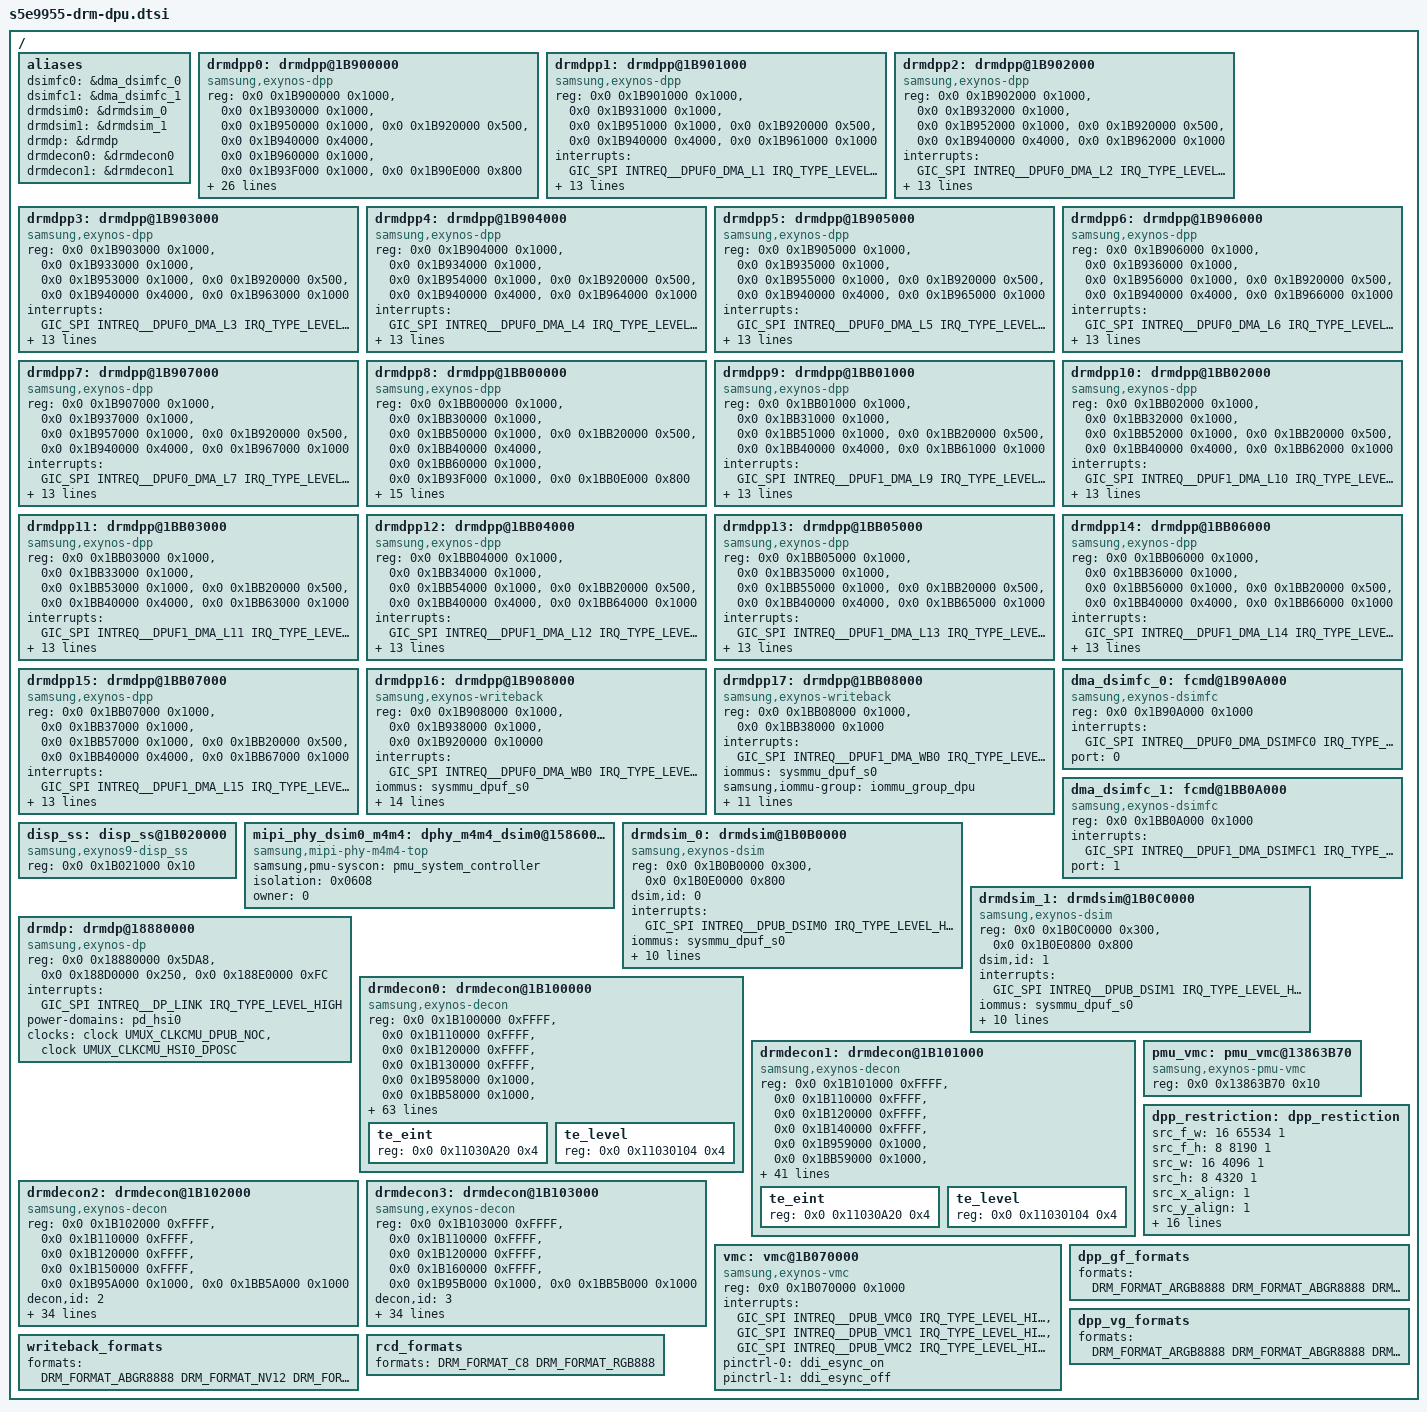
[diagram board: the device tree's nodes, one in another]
/*
 * SAMSUNG EXYNOS9945 SoC device tree source
 *
 * Copyright (c) 2021 Samsung Electronics Co., Ltd.
 *		http://www.samsung.com
 *
 * SAMSUNG EXYNOS9945 SoC device nodes are listed in this file.
 * EXYNOS based board files can include this file and provide
 * values for board specfic bindings.
 *
 * This program is free software; you can redistribute it and/or modify
 * it under the terms of the GNU General Public License version 2 as
 * published by the Free Software Foundation.
 */

#include <dt-bindings/interrupt-controller/arm-gic.h>
#include <dt-bindings/interrupt-controller/s5e9955.h>
#include <dt-bindings/clock/s5e9955.h>
#include <dt-bindings/soc/samsung/s5e9955-devfreq.h>
#include <dt-bindings/display/exynos-display.h>
#include "s5e9955-pinctrl.dtsi"
#include "s5e9955-display-timing.dtsi"
#include "s5e9955-pm-domains.dtsi"

/ {
	aliases {
		dsimfc0 = &dma_dsimfc_0;
		dsimfc1 = &dma_dsimfc_1;
		drmdsim0 = &drmdsim_0;
		drmdsim1 = &drmdsim_1;
		drmdp = &drmdp;
		drmdecon0 = &drmdecon0;
		drmdecon1 = &drmdecon1;
	};

	drmdpp0: drmdpp@1B900000 {	/* L0 */
		compatible = "samsung,exynos-dpp";
		reg = <0x0 0x1B900000 0x1000>,	/* DPU_DMA */
		      <0x0 0x1B930000 0x1000>,	/* DPP */
		      <0x0 0x1B950000 0x1000>,	/* SRAMCON */
		      <0x0 0x1B920000 0x500>,	/* vOTF_DPUF0 */
		      <0x0 0x1B940000 0x4000>,  /* SCL_COEF */
		      <0x0 0x1B960000 0x1000>,  /* HDR_COMM */
		      <0x0 0x1B93F000 0x1000>,  /* DPP_DEBUG */
		      <0x0 0x1B90E000 0x800>;   /* SFR_DMA */
		reg-names = "dma", "dpp", "sramc", "votf",
			    "scl_coef", "hdr_comm", "dpp_debug", "sfr_dma";

		/* DPU_DMA IRQ, DPP IRQ, SFR_DMA IRQ */
		interrupts = <GIC_SPI INTREQ__DPUF0_DMA_L0 IRQ_TYPE_LEVEL_HIGH>;
		interrupt-names = "dma";

		iommus = <&sysmmu_dpuf_s0>;
		samsung,iommu-group = <&iommu_group_dpu>;
		/* vOTF_MSCL(for vOTF sysmmu) */
		samsung,iommu-identity-map = <0x0 0x1D890000 0x10000>;

		attr = <(DPP_ATTR_SAJC | DPP_ATTR_FLIP | DPP_ATTR_IDMA |
			DPP_ATTR_DPP | DPP_ATTR_SRAMC | DPP_ATTR_HDR_COMM)>;
		port = <0>; /* AXI port number */

		/* 1: scale X, 2: 1/2x scale down, 4: 1/4x scale down */
		scale_down = <1>;
		/* 1: scale X, 2: 2x scale up, 4: 4x scale up */
		scale_up = <1>;

		dpp,id = <0>;
		dpuf,id = <0>;
		dpp,formats = <&dpp_gf_formats>;
		dpp,restriction = <&dpp_restriction>;
		dpp,comp-transform-support = <(COMP_RGB_FLIP_ALL)>;

		//dpp,rsc_check;
		rsc_sajc = <1>;
		rsc_sbwc = <2>;
		rsc_rot = <1>;
		rsc_scl = <2>;
		rsc_itp_csc = <4>;
		rsc_sramc = <2>;
		rsc_sram_w = <1024>;
		rsc_sram = <42>;

		dpp,enable-dma-write-mode;
	};

	drmdpp1: drmdpp@1B901000 {	/* L1 */
		compatible = "samsung,exynos-dpp";
		reg = <0x0 0x1B901000 0x1000>,
		      <0x0 0x1B931000 0x1000>,
		      <0x0 0x1B951000 0x1000>,
		      <0x0 0x1B920000 0x500>,
		      <0x0 0x1B940000 0x4000>,
		      <0x0 0x1B961000 0x1000>;
		reg-names = "dma", "dpp", "sramc", "votf", "scl_coef", "hdr_comm";

		interrupts = <GIC_SPI INTREQ__DPUF0_DMA_L1 IRQ_TYPE_LEVEL_HIGH>;
		interrupt-names = "dma";

		iommus = <&sysmmu_dpuf_s0>;
		samsung,iommu-group = <&iommu_group_dpu>;

		attr = <(DPP_ATTR_SAJC | DPP_ATTR_FLIP | DPP_ATTR_ROT |
			DPP_ATTR_CSC | DPP_ATTR_SCALE |	DPP_ATTR_SBWC |
			DPP_ATTR_IDMA |	DPP_ATTR_DPP | DPP_ATTR_SRAMC |
			DPP_ATTR_HDR_COMM)>;
		port = <0>;
		scale_down = <4>;
		scale_up = <8>;

		dpp,id = <1>;
		dpuf,id = <0>;
		dpp,formats = <&dpp_vg_formats>;
		dpp,restriction = <&dpp_restriction>;
		dpp,comp-transform-support = <(COMP_YUV420_ALL | COMP_RGB_FLIP_ALL)>;
	};

	drmdpp2: drmdpp@1B902000 {	/* L2 */
		compatible = "samsung,exynos-dpp";
		reg = <0x0 0x1B902000 0x1000>,
		      <0x0 0x1B932000 0x1000>,
		      <0x0 0x1B952000 0x1000>,
		      <0x0 0x1B920000 0x500>,
		      <0x0 0x1B940000 0x4000>,
		      <0x0 0x1B962000 0x1000>;
		reg-names = "dma", "dpp", "sramc", "votf", "scl_coef", "hdr_comm";

		interrupts = <GIC_SPI INTREQ__DPUF0_DMA_L2 IRQ_TYPE_LEVEL_HIGH>;
		interrupt-names = "dma";

		iommus = <&sysmmu_dpuf_s0>;
		samsung,iommu-group = <&iommu_group_dpu>;

		attr = <(DPP_ATTR_SAJC | DPP_ATTR_FLIP | DPP_ATTR_IDMA |
			DPP_ATTR_DPP | DPP_ATTR_SRAMC | DPP_ATTR_HDR_COMM)>;
		port = <0>;
		scale_down = <1>;
		scale_up = <1>;

		dpp,id = <2>;
		dpuf,id = <0>;
		dpp,formats = <&dpp_gf_formats>;
		dpp,restriction = <&dpp_restriction>;
		dpp,comp-transform-support = <(COMP_RGB_FLIP_ALL)>;
	};

	drmdpp3: drmdpp@1B903000 {	/* L3 */
		compatible = "samsung,exynos-dpp";
		reg = <0x0 0x1B903000 0x1000>,
		      <0x0 0x1B933000 0x1000>,
		      <0x0 0x1B953000 0x1000>,
		      <0x0 0x1B920000 0x500>,
		      <0x0 0x1B940000 0x4000>,
		      <0x0 0x1B963000 0x1000>;
		reg-names = "dma", "dpp", "sramc", "votf", "scl_coef", "hdr_comm";

		interrupts = <GIC_SPI INTREQ__DPUF0_DMA_L3 IRQ_TYPE_LEVEL_HIGH>;
		interrupt-names = "dma";

		iommus = <&sysmmu_dpuf_s0>;
		samsung,iommu-group = <&iommu_group_dpu>;

		attr = <(DPP_ATTR_SAJC | DPP_ATTR_FLIP | DPP_ATTR_ROT |
			DPP_ATTR_CSC | DPP_ATTR_SCALE |	DPP_ATTR_SBWC |
			DPP_ATTR_IDMA |	DPP_ATTR_DPP | DPP_ATTR_SRAMC |
			DPP_ATTR_HDR_COMM)>;
		port = <0>;
		scale_down = <4>;
		scale_up = <8>;

		dpp,id = <3>;
		dpuf,id = <0>;
		dpp,formats = <&dpp_vg_formats>;
		dpp,restriction = <&dpp_restriction>;
		dpp,comp-transform-support = <(COMP_YUV420_ALL | COMP_RGB_FLIP_ALL)>;
	};

	drmdpp4: drmdpp@1B904000 {	/* L4 */
		compatible = "samsung,exynos-dpp";
		reg = <0x0 0x1B904000 0x1000>,
		      <0x0 0x1B934000 0x1000>,
		      <0x0 0x1B954000 0x1000>,
		      <0x0 0x1B920000 0x500>,
		      <0x0 0x1B940000 0x4000>,
		      <0x0 0x1B964000 0x1000>;
		reg-names = "dma", "dpp", "sramc", "votf", "scl_coef", "hdr_comm";

		interrupts = <GIC_SPI INTREQ__DPUF0_DMA_L4 IRQ_TYPE_LEVEL_HIGH>;
		interrupt-names = "dma";

		iommus = <&sysmmu_dpuf_s0>;
		samsung,iommu-group = <&iommu_group_dpu>;

		attr = <(DPP_ATTR_SAJC | DPP_ATTR_FLIP | DPP_ATTR_IDMA |
			DPP_ATTR_DPP | DPP_ATTR_SRAMC | DPP_ATTR_HDR_COMM)>;
		port = <1>;
		scale_down = <1>;
		scale_up = <1>;

		dpp,id = <4>;
		dpuf,id = <0>;
		dpp,formats = <&dpp_gf_formats>;
		dpp,restriction = <&dpp_restriction>;
		dpp,comp-transform-support = <(COMP_RGB_FLIP_ALL)>;
	};

	drmdpp5: drmdpp@1B905000 {	/* L5 */
		compatible = "samsung,exynos-dpp";
		reg = <0x0 0x1B905000 0x1000>,
		      <0x0 0x1B935000 0x1000>,
		      <0x0 0x1B955000 0x1000>,
		      <0x0 0x1B920000 0x500>,
		      <0x0 0x1B940000 0x4000>,
		      <0x0 0x1B965000 0x1000>;
		reg-names = "dma", "dpp", "sramc", "votf", "scl_coef", "hdr_comm";

		interrupts = <GIC_SPI INTREQ__DPUF0_DMA_L5 IRQ_TYPE_LEVEL_HIGH>;
		interrupt-names = "dma";

		iommus = <&sysmmu_dpuf_s0>;
		samsung,iommu-group = <&iommu_group_dpu>;

		attr = <(DPP_ATTR_SAJC | DPP_ATTR_FLIP | DPP_ATTR_ROT |
			DPP_ATTR_CSC | DPP_ATTR_SCALE |	DPP_ATTR_SBWC |
			DPP_ATTR_IDMA |	DPP_ATTR_DPP | DPP_ATTR_SRAMC |
			DPP_ATTR_HDR_COMM)>;
		port = <1>;
		scale_down = <4>;
		scale_up = <8>;

		dpp,id = <5>;
		dpuf,id = <0>;
		dpp,formats = <&dpp_vg_formats>;
		dpp,restriction = <&dpp_restriction>;
		dpp,comp-transform-support = <(COMP_YUV420_ALL | COMP_RGB_FLIP_ALL)>;
	};

	drmdpp6: drmdpp@1B906000 {	/* L6 */
		compatible = "samsung,exynos-dpp";
		reg = <0x0 0x1B906000 0x1000>,
		      <0x0 0x1B936000 0x1000>,
		      <0x0 0x1B956000 0x1000>,
		      <0x0 0x1B920000 0x500>,
		      <0x0 0x1B940000 0x4000>,
		      <0x0 0x1B966000 0x1000>;
		reg-names = "dma", "dpp", "sramc", "votf", "scl_coef", "hdr_comm";

		interrupts = <GIC_SPI INTREQ__DPUF0_DMA_L6 IRQ_TYPE_LEVEL_HIGH>;
		interrupt-names = "dma";

		iommus = <&sysmmu_dpuf_s0>;
		samsung,iommu-group = <&iommu_group_dpu>;

		attr = <(DPP_ATTR_SAJC | DPP_ATTR_FLIP | DPP_ATTR_IDMA |
			DPP_ATTR_DPP | DPP_ATTR_SRAMC | DPP_ATTR_HDR_COMM)>;
		port = <1>;
		scale_down = <1>;
		scale_up = <1>;

		dpp,id = <6>;
		dpuf,id = <0>;
		dpp,formats = <&dpp_gf_formats>;
		dpp,restriction = <&dpp_restriction>;
		dpp,comp-transform-support = <(COMP_RGB_FLIP_ALL)>;
	};

	drmdpp7: drmdpp@1B907000 {	/* L7 */
		compatible = "samsung,exynos-dpp";
		reg = <0x0 0x1B907000 0x1000>,
		      <0x0 0x1B937000 0x1000>,
		      <0x0 0x1B957000 0x1000>,
		      <0x0 0x1B920000 0x500>,
		      <0x0 0x1B940000 0x4000>,
		      <0x0 0x1B967000 0x1000>;
		reg-names = "dma", "dpp", "sramc", "votf", "scl_coef", "hdr_comm";

		interrupts = <GIC_SPI INTREQ__DPUF0_DMA_L7 IRQ_TYPE_LEVEL_HIGH>;
		interrupt-names = "dma";

		iommus = <&sysmmu_dpuf_s0>;
		samsung,iommu-group = <&iommu_group_dpu>;

		attr = <(DPP_ATTR_SAJC | DPP_ATTR_FLIP | DPP_ATTR_ROT |
			DPP_ATTR_CSC | DPP_ATTR_SCALE |	DPP_ATTR_SBWC |
			DPP_ATTR_IDMA |	DPP_ATTR_DPP | DPP_ATTR_SRAMC |
			DPP_ATTR_HDR_COMM)>;
		port = <1>;
		scale_down = <4>;
		scale_up = <8>;

		dpp,id = <7>;
		dpuf,id = <0>;
		dpp,formats = <&dpp_vg_formats>;
		dpp,restriction = <&dpp_restriction>;
		dpp,comp-transform-support = <(COMP_YUV420_ALL | COMP_RGB_FLIP_ALL)>;
	};

	drmdpp8: drmdpp@1BB00000 {	/* L8 */
		compatible = "samsung,exynos-dpp";
		reg = <0x0 0x1BB00000 0x1000>,
		      <0x0 0x1BB30000 0x1000>,
		      <0x0 0x1BB50000 0x1000>,
		      <0x0 0x1BB20000 0x500>,
		      <0x0 0x1BB40000 0x4000>,
		      <0x0 0x1BB60000 0x1000>,
		      <0x0 0x1B93F000 0x1000>,
		      <0x0 0x1BB0E000 0x800>;
		reg-names = "dma", "dpp", "sramc", "votf", "scl_coef",
			"hdr_comm", "dpp_debug", "sfr_dma";

		interrupts = <GIC_SPI INTREQ__DPUF1_DMA_L8 IRQ_TYPE_LEVEL_HIGH>;
		interrupt-names = "dma";

		iommus = <&sysmmu_dpuf_s0>;
		samsung,iommu-group = <&iommu_group_dpu>;

		attr = <(DPP_ATTR_SAJC | DPP_ATTR_FLIP | DPP_ATTR_IDMA |
			DPP_ATTR_DPP | DPP_ATTR_SRAMC | DPP_ATTR_HDR_COMM)>;
		port = <1>;
		scale_down = <1>;
		scale_up = <1>;

		dpp,id = <8>;
		dpuf,id = <1>;
		dpp,formats = <&dpp_gf_formats>;
		dpp,restriction = <&dpp_restriction>;
		dpp,comp-transform-support = <(COMP_RGB_FLIP_ALL)>;
	};

	drmdpp9: drmdpp@1BB01000 {	/* L9 */
		compatible = "samsung,exynos-dpp";
		reg = <0x0 0x1BB01000 0x1000>,
		      <0x0 0x1BB31000 0x1000>,
		      <0x0 0x1BB51000 0x1000>,
		      <0x0 0x1BB20000 0x500>,
		      <0x0 0x1BB40000 0x4000>,
		      <0x0 0x1BB61000 0x1000>;
		reg-names = "dma", "dpp", "sramc", "votf", "scl_coef", "hdr_comm";

		interrupts = <GIC_SPI INTREQ__DPUF1_DMA_L9 IRQ_TYPE_LEVEL_HIGH>;
		interrupt-names = "dma";

		iommus = <&sysmmu_dpuf_s0>;
		samsung,iommu-group = <&iommu_group_dpu>;

		attr = <(DPP_ATTR_SAJC | DPP_ATTR_FLIP | DPP_ATTR_ROT |
			DPP_ATTR_CSC | DPP_ATTR_SCALE |	DPP_ATTR_SBWC |
			DPP_ATTR_IDMA |	DPP_ATTR_DPP | DPP_ATTR_SRAMC |
			DPP_ATTR_HDR_COMM)>;
		port = <1>;
		scale_down = <4>;
		scale_up = <8>;

		dpp,id = <9>;
		dpuf,id = <1>;
		dpp,formats = <&dpp_vg_formats>;
		dpp,restriction = <&dpp_restriction>;
		dpp,comp-transform-support = <(COMP_YUV420_ALL | COMP_RGB_FLIP_ALL)>;
	};

	drmdpp10: drmdpp@1BB02000 {	/* L10 */
		compatible = "samsung,exynos-dpp";
		reg = <0x0 0x1BB02000 0x1000>,
		      <0x0 0x1BB32000 0x1000>,
		      <0x0 0x1BB52000 0x1000>,
		      <0x0 0x1BB20000 0x500>,
		      <0x0 0x1BB40000 0x4000>,
		      <0x0 0x1BB62000 0x1000>;
		reg-names = "dma", "dpp", "sramc", "votf", "scl_coef", "hdr_comm";

		interrupts = <GIC_SPI INTREQ__DPUF1_DMA_L10 IRQ_TYPE_LEVEL_HIGH>;
		interrupt-names = "dma";

		iommus = <&sysmmu_dpuf_s0>;
		samsung,iommu-group = <&iommu_group_dpu>;

		attr = <(DPP_ATTR_SAJC | DPP_ATTR_FLIP | DPP_ATTR_IDMA |
			DPP_ATTR_DPP | DPP_ATTR_SRAMC | DPP_ATTR_HDR_COMM)>;
		port = <1>;
		scale_down = <1>;
		scale_up = <1>;

		dpp,id = <10>;
		dpuf,id = <1>;
		dpp,formats = <&dpp_gf_formats>;
		dpp,restriction = <&dpp_restriction>;
		dpp,comp-transform-support = <(COMP_RGB_FLIP_ALL)>;
	};

	drmdpp11: drmdpp@1BB03000 {	/* L11 */
		compatible = "samsung,exynos-dpp";
		reg = <0x0 0x1BB03000 0x1000>,
		      <0x0 0x1BB33000 0x1000>,
		      <0x0 0x1BB53000 0x1000>,
		      <0x0 0x1BB20000 0x500>,
		      <0x0 0x1BB40000 0x4000>,
		      <0x0 0x1BB63000 0x1000>;
		reg-names = "dma", "dpp", "sramc", "votf", "scl_coef", "hdr_comm";

		interrupts = <GIC_SPI INTREQ__DPUF1_DMA_L11 IRQ_TYPE_LEVEL_HIGH>;
		interrupt-names = "dma";

		iommus = <&sysmmu_dpuf_s0>;
		samsung,iommu-group = <&iommu_group_dpu>;

		attr = <(DPP_ATTR_SAJC | DPP_ATTR_FLIP | DPP_ATTR_ROT |
			DPP_ATTR_CSC | DPP_ATTR_SCALE |	DPP_ATTR_SBWC |
			DPP_ATTR_IDMA |	DPP_ATTR_DPP | DPP_ATTR_SRAMC |
			DPP_ATTR_HDR_COMM)>;
		port = <1>;
		scale_down = <4>;
		scale_up = <8>;

		dpp,id = <11>;
		dpuf,id = <1>;
		dpp,formats = <&dpp_vg_formats>;
		dpp,restriction = <&dpp_restriction>;
		dpp,comp-transform-support = <(COMP_YUV420_ALL | COMP_RGB_FLIP_ALL)>;
	};

	drmdpp12: drmdpp@1BB04000 {	/* L12 */
		compatible = "samsung,exynos-dpp";
		reg = <0x0 0x1BB04000 0x1000>,
		      <0x0 0x1BB34000 0x1000>,
		      <0x0 0x1BB54000 0x1000>,
		      <0x0 0x1BB20000 0x500>,
		      <0x0 0x1BB40000 0x4000>,
		      <0x0 0x1BB64000 0x1000>;
		reg-names = "dma", "dpp", "sramc", "votf", "scl_coef", "hdr_comm";

		interrupts = <GIC_SPI INTREQ__DPUF1_DMA_L12 IRQ_TYPE_LEVEL_HIGH>;
		interrupt-names = "dma";

		iommus = <&sysmmu_dpuf_s0>;
		samsung,iommu-group = <&iommu_group_dpu>;

		attr = <(DPP_ATTR_SAJC | DPP_ATTR_FLIP | DPP_ATTR_IDMA |
			DPP_ATTR_DPP | DPP_ATTR_SRAMC | DPP_ATTR_HDR_COMM)>;
		port = <0>;
		scale_down = <1>;
		scale_up = <1>;

		dpp,id = <12>;
		dpuf,id = <1>;
		dpp,formats = <&dpp_gf_formats>;
		dpp,restriction = <&dpp_restriction>;
		dpp,comp-transform-support = <(COMP_RGB_FLIP_ALL)>;
	};

	drmdpp13: drmdpp@1BB05000 {	/* L13 */
		compatible = "samsung,exynos-dpp";
		reg = <0x0 0x1BB05000 0x1000>,
		      <0x0 0x1BB35000 0x1000>,
		      <0x0 0x1BB55000 0x1000>,
		      <0x0 0x1BB20000 0x500>,
		      <0x0 0x1BB40000 0x4000>,
		      <0x0 0x1BB65000 0x1000>;
		reg-names = "dma", "dpp", "sramc", "votf", "scl_coef", "hdr_comm";

		interrupts = <GIC_SPI INTREQ__DPUF1_DMA_L13 IRQ_TYPE_LEVEL_HIGH>;
		interrupt-names = "dma";

		iommus = <&sysmmu_dpuf_s0>;
		samsung,iommu-group = <&iommu_group_dpu>;

		attr = <(DPP_ATTR_SAJC | DPP_ATTR_FLIP | DPP_ATTR_ROT |
			DPP_ATTR_CSC | DPP_ATTR_SCALE |	DPP_ATTR_SBWC |
			DPP_ATTR_IDMA |	DPP_ATTR_DPP | DPP_ATTR_SRAMC |
			DPP_ATTR_HDR_COMM)>;
		port = <0>;
		scale_down = <4>;
		scale_up = <8>;

		dpp,id = <13>;
		dpuf,id = <1>;
		dpp,formats = <&dpp_vg_formats>;
		dpp,restriction = <&dpp_restriction>;
		dpp,comp-transform-support = <(COMP_YUV420_ALL | COMP_RGB_FLIP_ALL)>;
	};

	drmdpp14: drmdpp@1BB06000 {	/* L14 */
		compatible = "samsung,exynos-dpp";
		reg = <0x0 0x1BB06000 0x1000>,
		      <0x0 0x1BB36000 0x1000>,
		      <0x0 0x1BB56000 0x1000>,
		      <0x0 0x1BB20000 0x500>,
		      <0x0 0x1BB40000 0x4000>,
		      <0x0 0x1BB66000 0x1000>;
		reg-names = "dma", "dpp", "sramc", "votf", "scl_coef", "hdr_comm";

		interrupts = <GIC_SPI INTREQ__DPUF1_DMA_L14 IRQ_TYPE_LEVEL_HIGH>;
		interrupt-names = "dma";

		iommus = <&sysmmu_dpuf_s0>;
		samsung,iommu-group = <&iommu_group_dpu>;

		attr = <(DPP_ATTR_SAJC | DPP_ATTR_FLIP | DPP_ATTR_IDMA |
			DPP_ATTR_DPP | DPP_ATTR_SRAMC | DPP_ATTR_HDR_COMM)>;
		port = <0>;
		scale_down = <1>;
		scale_up = <1>;

		dpp,id = <14>;
		dpuf,id = <1>;
		dpp,formats = <&dpp_gf_formats>;
		dpp,restriction = <&dpp_restriction>;
		dpp,comp-transform-support = <(COMP_RGB_FLIP_ALL)>;
	};

	drmdpp15: drmdpp@1BB07000 {	/* L15 */
		compatible = "samsung,exynos-dpp";
		reg = <0x0 0x1BB07000 0x1000>,
		      <0x0 0x1BB37000 0x1000>,
		      <0x0 0x1BB57000 0x1000>,
		      <0x0 0x1BB20000 0x500>,
		      <0x0 0x1BB40000 0x4000>,
		      <0x0 0x1BB67000 0x1000>;
		reg-names = "dma", "dpp", "sramc", "votf", "scl_coef", "hdr_comm";

		interrupts = <GIC_SPI INTREQ__DPUF1_DMA_L15 IRQ_TYPE_LEVEL_HIGH>;
		interrupt-names = "dma";

		iommus = <&sysmmu_dpuf_s0>;
		samsung,iommu-group = <&iommu_group_dpu>;

		attr = <(DPP_ATTR_SAJC | DPP_ATTR_FLIP | DPP_ATTR_ROT |
			DPP_ATTR_CSC | DPP_ATTR_SCALE |	DPP_ATTR_SBWC |
			DPP_ATTR_IDMA |	DPP_ATTR_DPP | DPP_ATTR_SRAMC |
			DPP_ATTR_HDR_COMM)>;
		port = <0>;
		scale_down = <4>;
		scale_up = <8>;

		dpp,id = <15>;
		dpuf,id = <1>;
		dpp,formats = <&dpp_vg_formats>;
		dpp,restriction = <&dpp_restriction>;
		dpp,comp-transform-support = <(COMP_YUV420_ALL | COMP_RGB_FLIP_ALL)>;
	};

	drmdpp16: drmdpp@1B908000 {
		compatible = "samsung,exynos-writeback";
		reg = <0x0 0x1B908000 0x1000>,
			  <0x0 0x1B938000 0x1000>,
			  <0x0 0x1B920000 0x10000>;
		reg-names = "dma", "dpp", "votf";

		interrupts = <GIC_SPI INTREQ__DPUF0_DMA_WB0 IRQ_TYPE_LEVEL_HIGH>;
		interrupt-names = "dma";

		iommus = <&sysmmu_dpuf_s0>;
		samsung,iommu-group = <&iommu_group_dpu>;
		/* vOTF_MFC(for vOTF sysmmu) */
		samsung,iommu-identity-map = <0x0 0x1E070000 0x10000>;

		attr = <(DPP_ATTR_CSC | DPP_ATTR_ODMA | DPP_ATTR_DPP)>;
		port = <1>;
		scale_down = <1>;
		scale_up = <1>;

		votf_o,enabled;
		votf_o,mfc_base = <0x1E070000>;

		dpp,id = <16>;
		dpuf,id = <0>;
		dpp,formats = <&writeback_formats>;
		dpp,restriction = <&dpp_restriction>;
	};

	drmdpp17: drmdpp@1BB08000 {
		compatible = "samsung,exynos-writeback";
		reg = <0x0 0x1BB08000 0x1000>,
			  <0x0 0x1BB38000 0x1000>;
		reg-names = "dma", "dpp";

		interrupts = <GIC_SPI INTREQ__DPUF1_DMA_WB0 IRQ_TYPE_LEVEL_HIGH>;
		interrupt-names = "dma";

		iommus = <&sysmmu_dpuf_s0>;
		samsung,iommu-group = <&iommu_group_dpu>;

		attr = <(DPP_ATTR_CSC | DPP_ATTR_ODMA | DPP_ATTR_DPP)>;
		port = <0>;
		scale_down = <1>;
		scale_up = <1>;

		votf_o,enabled;
		votf_o,mfc_base = <0x1E070000>;

		dpp,id = <17>;
		dpuf,id = <1>;
		dpp,formats = <&writeback_formats>;
		dpp,restriction = <&dpp_restriction>;
	};

	dma_dsimfc_0: fcmd@1B90A000 {	/* DPUF0_DSIMFC_L0 */
		compatible = "samsung,exynos-dsimfc";
		/* DPU_DMA */
		reg = <0x0 0x1B90A000 0x1000>;
		/* DPU_DMA IRQ */
		interrupts = <GIC_SPI INTREQ__DPUF0_DMA_DSIMFC0 IRQ_TYPE_LEVEL_HIGH>;
		interrupt-names = "dsimfc";
		port = <0>; /* AXI port number */
	};

	dma_dsimfc_1: fcmd@1BB0A000 {	/* DPUF1_DSIMFC_L1 */
		compatible = "samsung,exynos-dsimfc";
		/* DPU_DMA */
		reg = <0x0 0x1BB0A000 0x1000>;
		/* DPU_DMA IRQ */
		interrupts = <GIC_SPI INTREQ__DPUF1_DMA_DSIMFC1 IRQ_TYPE_LEVEL_HIGH>;
		interrupt-names = "dsimfc";
		port = <1>; /* AXI port number */
	};

	disp_ss: disp_ss@1B020000 {
		compatible = "samsung,exynos9-disp_ss";
		reg = <0x0 0x1B021000 0x10>;
		reg-names = "sys";
	};

	mipi_phy_dsim0_m4m4: dphy_m4m4_dsim0@15860000 {
		compatible = "samsung,mipi-phy-m4m4-top";
		samsung,pmu-syscon = <&pmu_system_controller>;
		isolation = <0x0608>;	/* offset is same as 9945 */
		owner = <0>; /* 0: DSI_0 1: DSI_1 */
		#phy-cells = <1>;
	};

	drmdsim_0: drmdsim@1B0B0000 {
		compatible = "samsung,exynos-dsim";
		reg = <0x0 0x1B0B0000 0x300>,	/* DSIM0 */
		      <0x0 0x1B0E0000 0x800>;	/* DCPHY-M0 */
		reg-names = "dsi", "dphy";

		dsim,id = <0>;

		interrupts = <GIC_SPI INTREQ__DPUB_DSIM0 IRQ_TYPE_LEVEL_HIGH>;
		interrupt-names = "dsim";

		iommus = <&sysmmu_dpuf_s0>;
		samsung,iommu-group = <&iommu_group_dpu>;

		phys = <&mipi_phy_dsim0_m4m4 0>;
		phy-names = "dsim_dphy";

		dsim_mode = <&dsim_modes>;

		clock-names = "oscclk_dsim";
		clocks = <&clock DOUT_DIV_CLK_DPUB_OSCCLK_DSIM>;

		dsi-burst-cmd = <1>;

		frequency-hopping;
		//wide-frequency-hopping;
		ulps-exit-fh-skip;

		pll-sleep = <DPHY_SLEEP_CTRL_LINK>;

		g_cmd_sram = <1024>;		/* sram for general command (unit : byte) */
		s_cmd_sram = <1024>;		/* sram for sync command (unit : byte)) */

		#address-cells = <1>;
		#size-cells = <0>;
	};

	drmdsim_1: drmdsim@1B0C0000 {
		compatible = "samsung,exynos-dsim";
		reg = <0x0 0x1B0C0000 0x300>,	/* DSIM1 */
		      <0x0 0x1B0E0800 0x800>;	/* DCPHY-M1 */
		reg-names = "dsi", "dphy";

		dsim,id = <1>;

		interrupts = <GIC_SPI INTREQ__DPUB_DSIM1 IRQ_TYPE_LEVEL_HIGH>;
		interrupt-names = "dsim";

		iommus = <&sysmmu_dpuf_s0>;
		samsung,iommu-group = <&iommu_group_dpu>;

		phys = <&mipi_phy_dsim0_m4m4 0>;
		phy-names = "dsim_dphy";

		dsim_mode = <&dsim_modes>;

		clock-names = "oscclk_dsim";
		clocks = <&clock DOUT_DIV_CLK_DPUB_OSCCLK_DSIM>;

		dsi-burst-cmd = <1>;

		frequency-hopping;
		//wide-frequency-hopping;
		ulps-exit-fh-skip;

		pll-sleep = <DPHY_SLEEP_CTRL_LINK>;

		g_cmd_sram = <1024>;		/* sram for general command (unit : byte) */
		s_cmd_sram = <1024>;		/* sram for sync command (unit : byte)) */

		#address-cells = <1>;
		#size-cells = <0>;
	};

	drmdp: drmdp@18880000 {
		compatible = "samsung,exynos-dp";
		/* IP resources(address, irq, sysmmu, power, secure, clock) */
		reg = <0x0 0x18880000 0x5DA8>,
			<0x0 0x188D0000 0x250>,
			<0x0 0x188E0000 0xFC>;
		reg-names = "dp_link", "usbdpphy_ctrl", "usbdpphy_tca_ctrl";

		interrupts = <GIC_SPI INTREQ__DP_LINK IRQ_TYPE_LEVEL_HIGH>;
		interrupt-names = "dp";

		power-domains = <&pd_hsi0>;
		/* clock */
		clock-names = "aclk", "dposc_clk";
		clocks = <&clock UMUX_CLKCMU_DPUB_NOC>, <&clock UMUX_CLKCMU_HSI0_DPOSC>;
	};

	drmdecon0: drmdecon@1B100000 {
		compatible = "samsung,exynos-decon";
		reg = <0x0 0x1B100000 0xFFFF>,	/* DECON0_MAIN */
		      <0x0 0x1B110000 0xFFFF>,	/* DECON_WIN */
		      <0x0 0x1B120000 0xFFFF>,	/* DECON_SUB */
		      <0x0 0x1B130000 0xFFFF>,	/* DECON0_WINCON */
		      <0x0 0x1B958000 0x1000>,	/* SRAMC0_D0 - DPUF0 */
		      <0x0 0x1BB58000 0x1000>,	/* SRAMC1_D0 - DPUF1 */
		      <0x0 0x1B90E000 0x1000>,  /* DQE EDMA*/
		      <0x0 0x1B170000 0xFFFF>;	/* DQE */
		reg-names = "main", "win", "sub", "wincon", "sramc_d",
			    "sramc1_d", "edma", "dqe";

		decon,id = <0>;

		interrupts = <GIC_SPI INTREQ__DPUB_DECON0_FRAME_START
				IRQ_TYPE_LEVEL_HIGH>,
			     <GIC_SPI INTREQ__DPUB_DECON0_FRAME_DONE
				IRQ_TYPE_LEVEL_HIGH>,
			     <GIC_SPI INTREQ__DPUB_DECON0_EXTRA
				IRQ_TYPE_LEVEL_HIGH>,
			     <GIC_SPI INTREQ__DPUF0_DMA_CGCTRL0
				IRQ_TYPE_LEVEL_HIGH>,
				 <GIC_SPI INTREQ__DPUF0_SRAMCON_D0
				IRQ_TYPE_LEVEL_HIGH>,
				 <GIC_SPI INTREQ__DPUF1_SRAMCON_D0
				IRQ_TYPE_LEVEL_HIGH>;
		interrupt-names = "frame_start", "frame_done", "extra",
				  "edma", "sramc_d", "sramc1_d";

		dpuf,pd-names = "pd_dpuf0", "pd_dpuf1";
		iommus = <&sysmmu_dpuf_s0>;
		samsung,iommu-group = <&iommu_group_dpu>;

		/* devfreq index */
		samsung,devfreq-idx = <DEVFREQ_MIF DEVFREQ_INT DEVFREQ_DISP>;

		/* clock */
		//clock-names = "aclk";
		//clocks = <&clock UMUX_CLKCMU_DPUB_NOC>;

		/* pinctrl */
		pinctrl-names = "hw_te_on", "hw_te_off";
		pinctrl-0 = <&decon_0_te_on>;
		pinctrl-1 = <&decon_0_te_off>;

		max_win = <16>;
		trig_mode = <0>;   /* 0: hw trigger, 1: sw trigger */
		out_type = <0x1>; /* BIT0:DSI0, BIT1:DSI1, BIT4:DP0, BIT5:DP1 */
		support-seamless-opmode-switch;

		/* 0: from DDI0, 1: from DDI1, 2: from DDI2 3: not receive TE */
		te_from = <0>;

		/* command mode svsync time (usec) */
		svsync_time_us = <1000>;
		svsync_on_fps = <120>;

		/* BTS */
		ppc = <2>;			/* pixel per clock */
		ppc_rotator = <8>;		/* rotator ppc */
		ppc_scaler = <4>;		/* scaler ppc */
		ppc_scaler_comp = <320>;	/* compressed + scaler, multipled by 100 */
		delay_comp = <4>;		/* line delay for sajc or sbwc : DMA */
		delay_scaler = <3>;		/* line delay for scaler : DPP */
		inner_width = <32>;		/* internal processing width */
		inner_util = <70>;		/* internal processing utill */
		vote-overlap-bw;

		/* bus info */
		bus_width = <32>;		/* 32-Byte : 256-bit bus */
		rot_util = <60>;		/* MIF_UTIL(65%) - 5%: UTIL gets worse at rotation */

		/* dpu dvfs */
		dfs_lv = <800000 663000 533000 468000 400000 332000 267000 200000 89000>;

		/* Urgent */
		rd_en = <1>; /* defaultly disable */
		rd_hi_thres = <0x7FF>;
		rd_lo_thres = <0x600>;
		rd_wait_cycle = <0x10>;
		wr_en = <0>; /* defaultly disable */
		wr_hi_thres = <0x0>;
		wr_lo_thres = <0x0>;

		/* DTA */
		dta_en = <0>; /* defaultly disable */
		dta_hi_thres = <0x7FC>;	/* recommended value on basis of 8K OF */
		dta_lo_thres = <0x400>;	/* recommended value on basis of 8K OF */

		/* DQE */
		dqe_preset_cnt = <0>;
		/*
		* <colormode(2Byte)|renderIntent(2Byte) x 4> for 1 preset
		* 0xFFFFFFFF: not set, 0xFFFF for CM or RI: select all
		* ex) 0xFFFF0006: all CM / 6 RI, 0x0001FFFF: 1 CM / all RI
		*/
		dqe_preset = 	<>;

		gpio_te = <&gpg2 0 0xf>;

		dpps = <&drmdpp0 &drmdpp1 &drmdpp2 &drmdpp3 &drmdpp4 &drmdpp5
			&drmdpp6 &drmdpp7 &drmdpp8 &drmdpp9 &drmdpp10
			&drmdpp11 &drmdpp12 &drmdpp13 &drmdpp14	&drmdpp15>;

		/* unit that is located at the very end of the decon
		 *      DQE=0
		 *      AIQE=1
		 */
		terminal-unit = <0>;

		/*
		 * connector type that can be connected to the DECON. please
		 * refer to enum exynos_drm_output_type in exynos_drm_drv.h
		 *
		 * DSI0(0x1), DSI1(0x2), VIDI(0x8)
		 */
		connector = <0x1 0x8>;

		hibernation;
		parent_dbgdev_pd = <&dbgdev_pd_vdd_mm>;
		partial-update;

		self-refresh = <1>;

		evt-mem = <0x40000>;
		fevt-mem = <0x8000>;
		log-mem0 = <0x20000>;
		log-mem1 = <0x4000>;

		#address-cells = <2>;
		#size-cells = <1>;
		ranges;

		/* sw te pending register */
		te_eint {
			/* NWEINT_GPG2_PEND */
			reg = <0x0 0x11030A20 0x4>;
		};

		/* te level register */
		te_level {
			/* GPG2_DAT */
			reg = <0x0 0x11030104 0x4>;
		};
	};

	drmdecon1: drmdecon@1B101000 {
		compatible = "samsung,exynos-decon";
		reg = <0x0 0x1B101000 0xFFFF>,	/* DECON0_MAIN */
		      <0x0 0x1B110000 0xFFFF>,	/* DECON_WIN */
		      <0x0 0x1B120000 0xFFFF>,	/* DECON_SUB */
		      <0x0 0x1B140000 0xFFFF>,	/* DECON0_WINCON */
		      <0x0 0x1B959000 0x1000>,	/* SRAMC0_D1 - DPUF0 */
		      <0x0 0x1BB59000 0x1000>,	/* SRAMC1_D1 - DPUF1 */
		      <0x0 0x1BB0E000 0x1000>,  /* DQE EDMA*/
		      <0x0 0x1B180000 0xFFFF>;  /* DQE */
		reg-names = "main", "win", "sub", "wincon", "sramc_d", "sramc1_d", "edma", "dqe";

		decon,id = <1>;

		interrupts = <GIC_SPI INTREQ__DPUB_DECON1_FRAME_START
				IRQ_TYPE_LEVEL_HIGH>,
			     <GIC_SPI INTREQ__DPUB_DECON1_FRAME_DONE
				IRQ_TYPE_LEVEL_HIGH>,
			     <GIC_SPI INTREQ__DPUB_DECON1_EXTRA
				IRQ_TYPE_LEVEL_HIGH>,
			     <GIC_SPI INTREQ__DPUF1_DMA_CGCTRL1
				IRQ_TYPE_LEVEL_HIGH>,
			     <GIC_SPI INTREQ__DPUF0_SRAMCON_D1
				IRQ_TYPE_LEVEL_HIGH>,
				 <GIC_SPI INTREQ__DPUF1_SRAMCON_D1
				IRQ_TYPE_LEVEL_HIGH>;
		interrupt-names = "frame_start", "frame_done", "extra",
				  "edma", "sramc_d", "sramc1_d";

		dpuf,pd-names = "pd_dpuf0", "pd_dpuf1";
		iommus = <&sysmmu_dpuf_s0>;
		samsung,iommu-group = <&iommu_group_dpu>;

		/* devfreq index */
		samsung,devfreq-idx = <DEVFREQ_MIF DEVFREQ_INT DEVFREQ_DISP>;

		/* clock */
		//clock-names = "aclk";
		//clocks = <&clock UMUX_CLKCMU_DPUB_NOC>;

		/* pinctrl */
		pinctrl-names = "hw_te_on", "hw_te_off";
		pinctrl-0 = <&decon_1_te_on>;
		pinctrl-1 = <&decon_1_te_off>;

		max_win = <16>;
		trig_mode = <0>;   /* 0: hw trigger, 1: sw trigger */
		out_type = <0x2>; /* BIT0:DSI0, BIT1:DSI1, BIT4:DP0, BIT5:DP1 */

		/* 0: from DDI0, 1: from DDI1, 2: from DDI2 3: not receive TE */
		te_from = <1>;

		/* BTS */ /* TODO: check olympus */
		ppc = <2>;		/* pixel per clock */
		ppc_rotator = <8>;		/* rotator ppc */
		ppc_scaler = <4>;		/* scaler ppc */
		delay_comp = <4>;		/* line delay for sajc or sbwc : DMA */
		delay_scaler = <3>;		/* line delay for scaler : DPP */
		inner_width = <32>;		/* internal processing width */
		inner_util = <70>;		/* internal processing utill */
		vote-overlap-bw;

		/* bus info */
		bus_width = <32>;		/* 32-Byte : 256-bit bus */
		rot_util = <60>;		/* MIF_UTIL(65%) - 5%: UTIL gets worse at rotation */

		/* dpu dvfs */
		dfs_lv = <800000 663000 533000 468000 400000 332000 267000 200000 89000>;

		gpio_te = <&gpg2 1 0xf>;

		dpps = <&drmdpp0 &drmdpp1 &drmdpp2 &drmdpp3 &drmdpp4 &drmdpp5
			&drmdpp6 &drmdpp7 &drmdpp8 &drmdpp9 &drmdpp10
			&drmdpp11 &drmdpp12 &drmdpp13 &drmdpp14	&drmdpp15>;

		/* unit that is located at the very end of the decon
		 *      DQE=0
		 *      AIQE=1
		 */
		terminal-unit = <0>;

		/*
		 * connector type that can be connected to the DECON. please
		 * refer to enum exynos_drm_output_type in exynos_drm_drv.h
		 *
		 * DSI0(0x1), DSI1(0x2), VIDI(0x8)
		 */
		connector = <0x2>;

		evt-mem = <0x4000>;
		fevt-mem = <0x2000>;

		#address-cells = <2>;
		#size-cells = <1>;
		ranges;

		/* sw te pending register */
		te_eint {
			/* NWEINT_GPG2_PEND */
			reg = <0x0 0x11030A20 0x4>;
		};

		/* te level register */
		te_level {
			/* GPG2_DAT */
			reg = <0x0 0x11030104 0x4>;
		};
	};

	drmdecon2: drmdecon@1B102000 {
		compatible = "samsung,exynos-decon";
		reg = <0x0 0x1B102000 0xFFFF>,
		      <0x0 0x1B110000 0xFFFF>,
		      <0x0 0x1B120000 0xFFFF>,
		      <0x0 0x1B150000 0xFFFF>,
		      <0x0 0x1B95A000 0x1000>,	/* SRAMC0_D2 - DPUF0 */
		      <0x0 0x1BB5A000 0x1000>;	/* SRAMC1_D2 - DPUF1 */
		reg-names = "main", "win", "sub", "wincon", "sramc_d", "sramc1_d";

		decon,id = <2>;

		interrupts = <GIC_SPI INTREQ__DPUB_DECON2_FRAME_START
				IRQ_TYPE_LEVEL_HIGH>,
			     <GIC_SPI INTREQ__DPUB_DECON2_FRAME_DONE
				IRQ_TYPE_LEVEL_HIGH>,
			     <GIC_SPI INTREQ__DPUB_DECON2_EXTRA
				IRQ_TYPE_LEVEL_HIGH>,
			     <GIC_SPI INTREQ__DPUF0_SRAMCON_D2
				IRQ_TYPE_LEVEL_HIGH>,
				 <GIC_SPI INTREQ__DPUF1_SRAMCON_D2
				IRQ_TYPE_LEVEL_HIGH>;
		interrupt-names = "frame_start", "frame_done", "extra",
				  "sramc_d", "sramc1_d";

		dpuf,pd-names = "pd_dpuf0", "pd_dpuf1";
		iommus = <&sysmmu_dpuf_s0>;
		samsung,iommu-group = <&iommu_group_dpu>;

		/* devfreq index */
		samsung,devfreq-idx = <DEVFREQ_MIF DEVFREQ_INT DEVFREQ_DISP>;

		/* clock */
		//clock-names = "aclk";
		//clocks = <&clock UMUX_CLKCMU_DPUB_NOC>;

		max_win = <16>;
		trig_mode = <0>;        /* 0: hw trigger, 1: sw trigger */
		out_type = <0x10>;/* BIT0:DSI0, BIT1:DSI1, BIT4:DP0, BIT5:DP1 */

		te_from = <0>;

		ppc = <2>;			/* pixel per clock */
		ppc_rotator = <8>;		/* rotator ppc */
		ppc_scaler = <4>;		/* scaler ppc */
		delay_comp = <4>;		/* line delay for sajc or sbwc : DMA */
		delay_scaler = <3>;		/* line delay for scaler : DPP */
		inner_width = <32>;		/* internal processing width */
		inner_util = <70>;		/* internal processing utill */
		vote-overlap-bw;

		/* bus info */
		bus_width = <32>;		/* 32-Byte : 256-bit bus */
		rot_util = <60>;		/* MIF_UTIL(65%) - 5%: UTIL gets worse at rotation */

		/* dpu dvfs */
		dfs_lv = <800000 663000 533000 468000 400000 332000 267000 200000 89000>;

		dpps = <&drmdpp0 &drmdpp1 &drmdpp2 &drmdpp3 &drmdpp4 &drmdpp5
			&drmdpp6 &drmdpp7 &drmdpp8 &drmdpp9 &drmdpp10
			&drmdpp11 &drmdpp12 &drmdpp13 &drmdpp14	&drmdpp15>;
		/* TODO: FIX for DP */
		connector = <0x10>;

		evt-mem = <0x4000>;
		fevt-mem = <0x2000>;
	};

	drmdecon3: drmdecon@1B103000 {
		compatible = "samsung,exynos-decon";
		reg = <0x0 0x1B103000 0xFFFF>,
		      <0x0 0x1B110000 0xFFFF>,
		      <0x0 0x1B120000 0xFFFF>,
		      <0x0 0x1B160000 0xFFFF>,
		      <0x0 0x1B95B000 0x1000>,	/* DPUF0_SRAMC_D3 */
		      <0x0 0x1BB5B000 0x1000>;	/* DPUF1_SRAMC_D3 */
		reg-names = "main", "win", "sub", "wincon", "sramc_d", "sramc1_d";

		decon,id = <3>;

		/* interrupt num : FRAME_START, FRMAE_DONE, EXTRA */
		interrupts = <GIC_SPI INTREQ__DPUB_DECON3_FRAME_START
				IRQ_TYPE_LEVEL_HIGH>,
			     <GIC_SPI INTREQ__DPUB_DECON3_FRAME_DONE
				IRQ_TYPE_LEVEL_HIGH>,
			     <GIC_SPI INTREQ__DPUB_DECON3_EXTRA
				IRQ_TYPE_LEVEL_HIGH>,
			     <GIC_SPI INTREQ__DPUF0_SRAMCON_D3
				IRQ_TYPE_LEVEL_HIGH>,
				 <GIC_SPI INTREQ__DPUF1_SRAMCON_D3
				IRQ_TYPE_LEVEL_HIGH>;
		interrupt-names = "frame_start", "frame_done", "extra",
				  "sramc_d", "sramc1_d";

		dpuf,pd-names = "pd_dpuf0", "pd_dpuf1";
		iommus = <&sysmmu_dpuf_s0>;
		samsung,iommu-group = <&iommu_group_dpu>;

		/* devfreq index */
		samsung,devfreq-idx = <DEVFREQ_MIF DEVFREQ_INT DEVFREQ_DISP>;

		/* clock */
		//clock-names = "aclk";
		//clocks = <&clock UMUX_CLKCMU_DPUB_NOC>;

		max_win = <16>;
		trig_mode = <1>;        /* 0: hw trigger, 1: sw trigger */
		out_type = <0x100>;/* BIT0:DSI0, BIT1:DSI1, BIT4:DP0, BIT5:DP1 BIT8: WB */

		te_from = <0>;

		ppc = <2>;			/* pixel per clock */
		ppc_rotator = <8>;		/* rotator ppc */
		ppc_scaler = <4>;		/* scaler ppc */
		delay_comp = <4>;		/* line delay for sajc or sbwc : DMA */
		delay_scaler = <3>;		/* line delay for scaler : DPP */
		inner_width = <32>;		/* internal processing width */
		inner_util = <70>;		/* internal processing utill */
		vote-overlap-bw;

		/* bus info */
		bus_width = <32>;		/* 32-Byte : 256-bit bus */
		rot_util = <60>;		/* MIF_UTIL(65%) - 5%: UTIL gets worse at rotation */

		/* dpu dvfs */
		dfs_lv = <800000 663000 533000 468000 400000 332000 267000 200000 89000>;

		dpps = <&drmdpp0 &drmdpp1 &drmdpp2 &drmdpp3 &drmdpp4 &drmdpp5
			&drmdpp6 &drmdpp7 &drmdpp8 &drmdpp9 &drmdpp10
			&drmdpp11 &drmdpp12 &drmdpp13 &drmdpp14	&drmdpp15>;
		connector = <0x8>;

		evt-mem = <0x4000>;
		fevt-mem = <0x2000>;
	};

	pmu_vmc: pmu_vmc@13863B70 {
		compatible = "samsung,exynos-pmu-vmc";
		reg = <0x0 0x13863B70 0x10>;
	};

	vmc: vmc@1B070000 {
		compatible = "samsung,exynos-vmc";
		reg = <0x0 0x1B070000 0x1000>;
		reg-names = "vmc";

		interrupts = <GIC_SPI INTREQ__DPUB_VMC0 IRQ_TYPE_LEVEL_HIGH>,
			     <GIC_SPI INTREQ__DPUB_VMC1 IRQ_TYPE_LEVEL_HIGH>,
			     <GIC_SPI INTREQ__DPUB_VMC2 IRQ_TYPE_LEVEL_HIGH>;
		interrupt-names = "wakeup", "vsync_frm", "vsync_frm_mod";

		/* pinctrl for DDI_ESYNC */
		pinctrl-names = "vmc_esync_on", "vmc_esync_off";
		pinctrl-0 = <&ddi_esync_on>;
		pinctrl-1 = <&ddi_esync_off>;
	};

	dpp_restriction: dpp_restiction {
		src_f_w = <16 65534 1>; /* min, max, align */
		src_f_h = <8 8190 1>;
		src_w = <16 4096 1>;
		src_h = <8 4320 1>;
		src_x_align = <1>;
		src_y_align = <1>;

		src_rgb_comp_f_w = <256 16128 256>;
		src_rgb_comp_f_h = <128 8064 128>;
		src_rgb_comp_w = <16 4096 1>;
		src_rgb_comp_h = <8 4320 1>;

		dst_f_w = <16 8190 1>;
		dst_f_h = <8 4320 1>;
		dst_w = <16 4096 1>;
		dst_h = <8 4320 1>;
		dst_x_align = <1>;
		dst_y_align = <1>;

		blk_w = <4 4096 1>;
		blk_h = <4 4320 1>;
		blk_x_align = <1>;
		blk_y_align = <1>;

		src_w_rot_max = <8192>;
		src_h_rot_max = <2168>;
	};

	dpp_gf_formats: dpp_gf_formats {
		formats = <
			DRM_FORMAT_ARGB8888
			DRM_FORMAT_ABGR8888
			DRM_FORMAT_RGBA8888
			DRM_FORMAT_BGRA8888
			DRM_FORMAT_XRGB8888
			DRM_FORMAT_XBGR8888
			DRM_FORMAT_RGBX8888
			DRM_FORMAT_BGRX8888
			DRM_FORMAT_RGB565
			DRM_FORMAT_BGR565
			DRM_FORMAT_ARGB2101010
			DRM_FORMAT_ABGR2101010
			DRM_FORMAT_RGBA1010102
			DRM_FORMAT_BGRA1010102
			DRM_FORMAT_ARGB16161616F
			DRM_FORMAT_ABGR16161616F
		>;
	};

	dpp_vg_formats: dpp_vg_formats {
		formats = <
			DRM_FORMAT_ARGB8888
			DRM_FORMAT_ABGR8888
			DRM_FORMAT_RGBA8888
			DRM_FORMAT_BGRA8888
			DRM_FORMAT_XRGB8888
			DRM_FORMAT_XBGR8888
			DRM_FORMAT_RGBX8888
			DRM_FORMAT_BGRX8888
			DRM_FORMAT_RGB565
			DRM_FORMAT_BGR565
			DRM_FORMAT_ARGB2101010
			DRM_FORMAT_ABGR2101010
			DRM_FORMAT_RGBA1010102
			DRM_FORMAT_BGRA1010102
			DRM_FORMAT_ARGB16161616F
			DRM_FORMAT_ABGR16161616F
			DRM_FORMAT_NV12
			DRM_FORMAT_NV21
			DRM_FORMAT_P010
		>;
	};

	writeback_formats: writeback_formats {
		formats = <
			DRM_FORMAT_ABGR8888
			DRM_FORMAT_NV12
			DRM_FORMAT_P010
		>;
	};

	rcd_formats: rcd_formats {
		formats = <
			DRM_FORMAT_C8
			DRM_FORMAT_RGB888
		>;
	};
};
